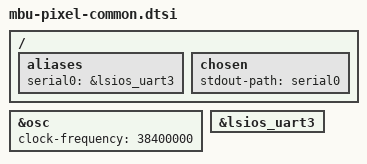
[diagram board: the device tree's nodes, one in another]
// SPDX-License-Identifier: GPL-2.0-only OR BSD-2-Clause
/*
 * Google Pixel 11 family common dtsi.
 *
 * Copyright 2025 Google LLC.
 */

#include "mbu.dtsi"

/ {
	aliases {
		serial0 = &lsios_uart3;
	};

	chosen {
		stdout-path = "serial0";
	};
};

&osc {
	clock-frequency = <38400000>;
};

&lsios_uart3 {
	status = "okay";
};
